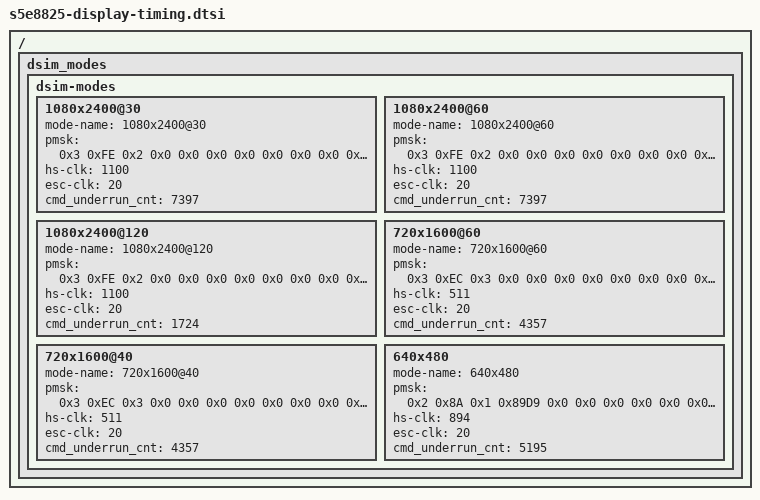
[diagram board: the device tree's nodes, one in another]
// SPDX-License-Identifier: GPL-2.0-only
/*
 * SAMSUNG EXYNOS SoC device tree source
 *
 * Copyright (c) 2019 Samsung Electronics Co., Ltd.
 *		http://www.samsung.com
 *
 */

/ {
	dsim_modes: dsim_modes {
		dsim-modes {
			    1080x2400@30 {
				mode-name = "1080x2400@30";
				pmsk = <
					0x3 0xFE 0x2 0x0 /* p m s k */
					0x0 0x0 0x0 0x0
					0x0 0x0 0x0 0x0
					0x0 0x0
					>;
				hs-clk = <1100>;
				esc-clk = <20>;
				cmd_underrun_cnt = <7397>;
			    };

			    1080x2400@60 {
				mode-name = "1080x2400@60";
				pmsk = <
					0x3 0xFE 0x2 0x0 /* p m s k */
					0x0 0x0 0x0 0x0
					0x0 0x0 0x0 0x0
					0x0 0x0
					>;
				hs-clk = <1100>;
				esc-clk = <20>;
				cmd_underrun_cnt = <7397>;
			    };

			    1080x2400@120 {
				mode-name = "1080x2400@120";
				pmsk = <
					0x3 0xFE 0x2 0x0 /* p m s k */
					0x0 0x0 0x0 0x0
					0x0 0x0 0x0 0x0
					0x0 0x0
					>;
				hs-clk = <1100>;
				esc-clk = <20>;
				cmd_underrun_cnt = <1724>;
			    };

			    720x1600@60 {
				mode-name = "720x1600@60";
				pmsk = <
					0x3 0xEC 0x3 0x0 /* p m s k */
					0x0 0x0 0x0 0x0
					0x0 0x0 0x0 0x0
					0x0 0x0
					>;
				hs-clk = <511>;
				esc-clk = <20>;
				cmd_underrun_cnt = <4357>;
			    };

			    720x1600@40 {
				mode-name = "720x1600@40";
				pmsk = <
					0x3 0xEC 0x3 0x0 /* p m s k */
					0x0 0x0 0x0 0x0
					0x0 0x0 0x0 0x0
					0x0 0x0
					>;
				hs-clk = <511>;
				esc-clk = <20>;
				cmd_underrun_cnt = <4357>;
			    };

			    /* for zebu emulator */
			    640x480 {
				mode-name = "640x480";
				pmsk = <
					0x2 0x8A 0x1 0x89D9 /* p m s k */
					0x0 0x0 0x0 0x0
					0x0 0x0 0x0 0x0
					0x0 0x0
					>;
				hs-clk = <894>;
				esc-clk = <20>;
				cmd_underrun_cnt = <5195>;
			    };
		};
	};
};
